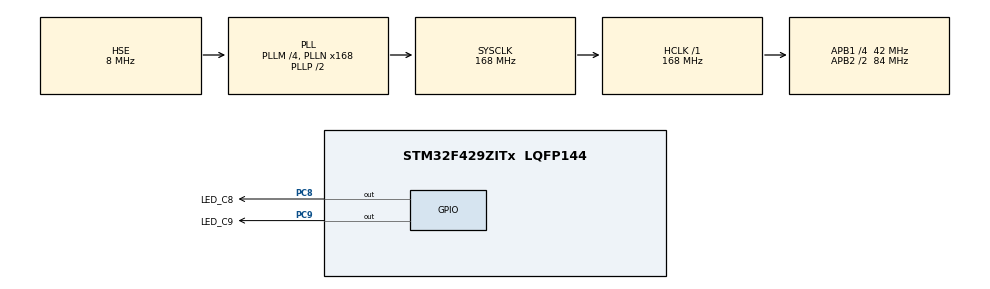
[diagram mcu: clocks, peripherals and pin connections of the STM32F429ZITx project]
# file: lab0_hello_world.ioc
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FREERTOS.Tasks01=defaultTask,24,128,StartDefaultTask,Default,NULL,Dynamic,NULL,NULL
Mcu.Family=STM32F4
Mcu.Name=STM32F429ZITx
Mcu.Package=LQFP144
NVIC.PriorityGroup=NVIC_PRIORITYGROUP_4
PA13.Mode=Serial_Wire
PA13.Signal=SYS_JTMS-SWDIO
PA14.Mode=Serial_Wire
PA14.Signal=SYS_JTCK-SWCLK
PC8.GPIO_Label=LED_C8
PC8.Signal=GPIO_Output
PC9.GPIO_Label=LED_C9
PC9.Signal=GPIO_Output
PH0/OSC_IN.Mode=HSE-External-Clock-Source
PH0/OSC_IN.Signal=RCC_OSC_IN
PH1/OSC_OUT.Mode=HSE-External-Clock-Source
PH1/OSC_OUT.Signal=RCC_OSC_OUT
ProjectManager.HeapSize=0x200
ProjectManager.StackSize=0x400
ProjectManager.TargetToolchain=MDK-ARM V5.32
RCC.48MHZClocksFreq_Value=48000000
RCC.AHBFreq_Value=168000000
RCC.APB1CLKDivider=RCC_HCLK_DIV4
RCC.APB1Freq_Value=42000000
RCC.APB1TimFreq_Value=84000000
RCC.APB2CLKDivider=RCC_HCLK_DIV2
RCC.APB2Freq_Value=84000000
RCC.APB2TimCLKDivider=2
RCC.APB2TimFreq_Value=168000000
RCC.CortexFreq_Value=168000000
RCC.HCLKFreq_Value=168000000
RCC.HSE_VALUE=8000000
RCC.HSI_VALUE=16000000
RCC.PLLM=4
RCC.PLLMUL=RCC_PLL_MUL9
RCC.PLLN=168
RCC.PLLQ=7
RCC.PLLSourceVirtual=RCC_PLLSOURCE_HSE
RCC.PRESCALERUSB=RCC_USBCLKSOURCE_PLL_DIV1_5
RCC.SYSCLKFreq_VALUE=168000000
RCC.SYSCLKSource=RCC_SYSCLKSOURCE_PLLCLK
RCC.SYSCLKSourceVirtual=RCC_SYSCLKSOURCE_PLLCLK
RCC.USBFreq_Value=48000000
RCC.VCOOutputFreq_Value=336000000
VP_FREERTOS_VS_CMSIS_V2.Mode=CMSIS_V2
board=NUCLEO-F429ZI

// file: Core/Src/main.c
/* USER CODE BEGIN Header */
/**
  ******************************************************************************
  * @file           : main.c
  * @brief          : Main program body
  ******************************************************************************
  * @attention
  *
  * Copyright (c) 2024 STMicroelectronics.
  * All rights reserved.
  *
  * This software is licensed under terms that can be found in the LICENSE file
  * in the root directory of this software component.
  * If no LICENSE file comes with this software, it is provided AS-IS.
  *
  ******************************************************************************
  */
/* USER CODE END Header */
#include "main.h"
//#include "cmsis_os.h"
#include "gpio.h"

/* USER CODE BEGIN Includes */
#include "FreeRTOS.h"
#include "task.h"
/* USER CODE END Includes */

/* USER CODE BEGIN PV */
TaskHandle_t handleLED_C8;
TaskHandle_t handleLED_C9;
/* USER CODE END PV */

void SystemClock_Config(void);

/* USER CODE BEGIN 0 */
void taskLED_C8(void *pvParm){
	while(1){
		HAL_GPIO_TogglePin(LED_C8_GPIO_Port, LED_C8_Pin);

		vTaskDelay(500);
	}
}

void taskLED_C9(void *pvParm){
	while(1){
		HAL_GPIO_TogglePin(LED_C9_GPIO_Port, LED_C9_Pin);

		vTaskDelay(100);
	}
}
/* USER CODE END 0 */

int main(void)
{

  /* MCU Configuration--------------------------------------------------------*/

  /* Reset of all peripherals, Initializes the Flash interface and the Systick. */
  HAL_Init();

  /* Configure the system clock */
  SystemClock_Config();

  /* Initialize all configured peripherals */
  MX_GPIO_Init();
  /* USER CODE BEGIN 2 */
	xTaskCreate(taskLED_C8, "LED C8", 128, NULL, 1, &handleLED_C8);
	xTaskCreate(taskLED_C9, "LED C9", 128, NULL, 1, &handleLED_C9);

	vTaskStartScheduler();
  /* USER CODE END 2 */

  /* Init scheduler */

  /* Start scheduler */

  /* We should never get here as control is now taken by the scheduler */
  /* Infinite loop */
  while (1)
  {

  }
}

void SystemClock_Config(void)
{
  RCC_OscInitTypeDef RCC_OscInitStruct = {0};
  RCC_ClkInitTypeDef RCC_ClkInitStruct = {0};

  /** Configure the main internal regulator output voltage
  */
  __HAL_RCC_PWR_CLK_ENABLE();
  __HAL_PWR_VOLTAGESCALING_CONFIG(PWR_REGULATOR_VOLTAGE_SCALE1);

  /** Initializes the RCC Oscillators according to the specified parameters
  * in the RCC_OscInitTypeDef structure.
  */
  RCC_OscInitStruct.OscillatorType = RCC_OSCILLATORTYPE_HSE;
  RCC_OscInitStruct.HSEState = RCC_HSE_BYPASS;
  RCC_OscInitStruct.PLL.PLLState = RCC_PLL_ON;
  RCC_OscInitStruct.PLL.PLLSource = RCC_PLLSOURCE_HSE;
  RCC_OscInitStruct.PLL.PLLM = 4;
  RCC_OscInitStruct.PLL.PLLN = 168;
  RCC_OscInitStruct.PLL.PLLP = RCC_PLLP_DIV2;
  RCC_OscInitStruct.PLL.PLLQ = 7;
  if (HAL_RCC_OscConfig(&RCC_OscInitStruct) != HAL_OK)
  {
    Error_Handler();
  }

  /** Initializes the CPU, AHB and APB buses clocks
  */
  RCC_ClkInitStruct.ClockType = RCC_CLOCKTYPE_HCLK|RCC_CLOCKTYPE_SYSCLK
                              |RCC_CLOCKTYPE_PCLK1|RCC_CLOCKTYPE_PCLK2;
  RCC_ClkInitStruct.SYSCLKSource = RCC_SYSCLKSOURCE_PLLCLK;
  RCC_ClkInitStruct.AHBCLKDivider = RCC_SYSCLK_DIV1;
  RCC_ClkInitStruct.APB1CLKDivider = RCC_HCLK_DIV4;
  RCC_ClkInitStruct.APB2CLKDivider = RCC_HCLK_DIV2;

  if (HAL_RCC_ClockConfig(&RCC_ClkInitStruct, FLASH_LATENCY_5) != HAL_OK)
  {
    Error_Handler();
  }
}

void Error_Handler(void)
{
  __disable_irq();
  while (1)
  {
  }
}
